# H6 register map
Vendor: Allwinner; Series: H6; File version: 0.1
CPU: CA53 0, little endian, MPU, no FPU, 0 interrupt priority bits
Registers are 32-bit, read-write, reset 0x0 unless marked. A register's access mark holds for its fields unless they carry their own. Offsets are from the block's base; [hi:lo] are bit positions; {n}, {i} and the like mark numbered series; 'fields as' and 'values as' point back to an identical list.

## PIO
Base 0x0300B000
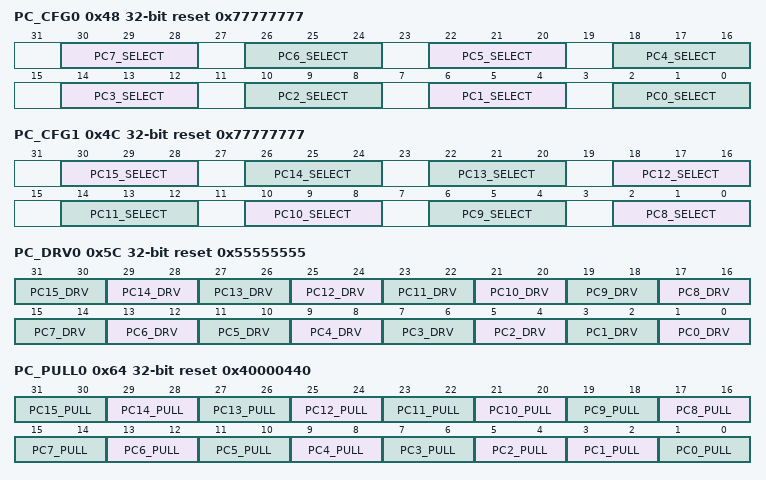
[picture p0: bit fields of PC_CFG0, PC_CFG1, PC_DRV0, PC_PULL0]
0x48 PC_CFG0 reset 0x77777777
  [30:28] PC7_SELECT — 000:Input 001:Output 010:NAND_DQ1 011:SDC2_D1 100:SPI0_WP 101:Reserved 110:Reserved 111:IO Disable
  [26:24] PC6_SELECT — 000:Input 001:Output 010:NAND_DQ0 011:SDC2_D0 100:SPI0_HOLD 101:Reserved 110:Reserved 111:IO Disable
  [22:20] PC5_SELECT — 000:Input 001:Output 010:NAND_RB0 011:SDC2_CMD 100:SPI0_CS 101:Reserved 110:Reserved 111:IO Disable
  [18:16] PC4_SELECT — 000:Input 001:Output 010:NAND_RE 011:SDC2_CLK 100:Reserved 101:Reserved 110:Reserved 111:IO Disable
  [14:12] PC3_SELECT — 000:Input 001:Output 010:NAND_CE0 011:Reserved 100:SPI0_MISO 101:Reserved 110:Reserved 111:IO Disable
  [10:8] PC2_SELECT — 000:Input 001:Output 010:NAND_CLE 011:Reserved 100:SPI0_MOSI 101:Reserved 110:Reserved 111:IO Disable
  [6:4] PC1_SELECT — 000:Input 001:Output 010:NAND_ALE 011:SDC2_DS 100:Reserved 101:Reserved 110:Reserved 111:IO Disable
  [2:0] PC0_SELECT — 000:Input 001:Output 010:NAND_WE 011:Reserved 100:SPI0_CLK 101:Reserved 110:Reserved 111:IO Disable
0x4C PC_CFG1 reset 0x77777777
  [30:28] PC15_SELECT — 000:Input 001:Output 010:NAND_CE1 011:Reserved 100:Reserved 101:Reserved 110:Reserved 111:IO Disable
  [26:24] PC14_SELECT — 000:Input 001:Output 010:NAND_DQS 011:SDC2_RST 100:Reserved 101:Reserved 110:Reserved 111:IO Disable
  [4n-30:4n-32] PC{n}_SELECT (n=8..13) — 000:Input 001:Output 010:NAND_DQ{n-6} 011:SDC2_D{n-6} 100:Reserved 101:Reserved 110:Reserved 111:IO Disable
0x50 PC_CFG2 reset 0x7
  [2:0] PC16_SELECT — 000:Input 001:Output 010:NAND_RB1 011:Reserved 100:Reserved 101:Reserved 110:Reserved 111:IO Disable
0x54 PC_CFG3 reset not defined
0x58 PC_DAT
  [16:0] PC_DAT — If the port is configured as input, the corresponding bit is the pin state. If the port is configured as output, the pin state is the same as the corresponding bit. The read bit value is the value setup by software. If the port is configured as functional pin, the undefined value will be read.
0x5C PC_DRV0 reset 0x55555555
  [all] fields
    {v}=Level_{v} (v=0..3)
  [2n+1:2n] PC{n}_DRV (n=0..15) — PC{n} Multi-Driving Select 00: Level 0 01: Level 1 10: Level 2 11: Level 3
0x60 PC_DRV1 reset 0x1
  [1:0] PC16_DRV — PC16 Multi-Driving Select 00: Level 0 01: Level 1 10: Level 2 11: Level 3
    {v}=Level_{v} (v=0..3)
0x64 PC_PULL0 reset 0x40000440
  [all] fields
    0=Pull_minus_up_slash_down_disable (Pull-up/down disable); 1=Pull_minus_up (Pull-up); 2=Pull_minus_down (Pull-down)
  [2n+1:2n] PC{n}_PULL (n=2..15) — PC{n} Pull-up/down Select 00: Pull-up/down disable 01: Pull-up 10: Pull-down 11: Reserved
  [3:2] PC1_PULL — PC Pull-up/down Select 00: Pull-up/down disable 01: Pull-up 10: Pull-down 11: Reserved
  [1:0] PC0_PULL — PC0 Pull-up/down Select 00: Pull-up/down disable 01: Pull-up 10: Pull-down 11: Reserved
0x68 PC_PULL1 reset 0x1
  [1:0] PC16_PULL — PC16 Pull-up/down Select 00: Pull-up/down disable 01: Pull-up 10: Pull-down 11: Reserved
    values as the fields of PC_PULL0
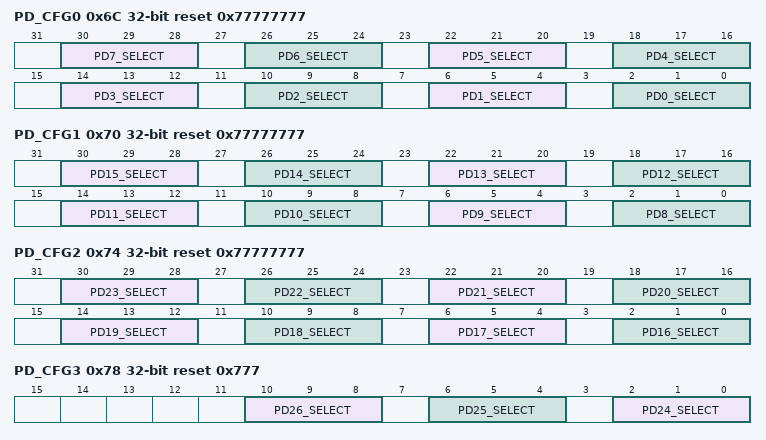
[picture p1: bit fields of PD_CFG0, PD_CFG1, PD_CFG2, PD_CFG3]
0x6C PD_CFG0 reset 0x77777777
  [30:28] PD7_SELECT — 000:Input 001:Output 010:LCD0_D11 011:TS0_D3 100:CSI_D3 101:RGMII_TXD3/RMII_NULL 110:Reserved 111:IO Disable
  [26:24] PD6_SELECT — 000:Input 001:Output 010:LCD0_D10 011:TS0_D2 100:CSI_D2 101:RGMII_NULL/RMII_RXER 110:Reserved 111:IO Disable
  [22:20] PD5_SELECT — 000:Input 001:Output 010:LCD0_D7 011:TS0_D1 100:CSI_D1 101:RGMII_RXCTL/RMII_CRS_DV 110:Reserved 111:IO Disable
  [18:16] PD4_SELECT — 000:Input 001:Output 010:LCD0_D6 011:TS0_D0 100:CSI_D0 101:RGMII_RXCK/RMII_NULL 110:Reserved 111:IO Disable
  [14:12] PD3_SELECT — 000:Input 001:Output 010:LCD0_D5 011:TS0_DVLD 100:CSI_VSYNC 101:RGMII_RXD0/RMII_RXD0 110:Reserved 111:IO Disable
  [10:8] PD2_SELECT — 000:Input 001:Output 010:LCD0_D4 011:TS0_SYNC 100:CSI_HSYNC 101:RGMII_RXD1/RMII_RXD1 110:Reserved 111:IO Disable
  [6:4] PD1_SELECT — 000:Input 001:Output 010:LCD0_D3 011:TS0_ERR 100:CSI_MCLK 101:RGMII_RXD2/RMII_NULL 110:Reserved 111:IO Disable
  [2:0] PD0_SELECT — 000:Input 001:Output 010:LCD0_D2 011:TS0_CLK 100:CSI_PCLK 101:RGMII_RXD3/RMII_NULL 110:Reserved 111:IO Disable
0x70 PD_CFG1 reset 0x77777777
  [30:28] PD15_SELECT — 000:Input 001:Output 010:LCD0_D21 011:TS1_DVLD 100:DMIC_DATA0 101:CSI_D9 110:Reserved 111:IO Disable
  [26:24] PD14_SELECT — 000:Input 001:Output 010:LCD0_D20 011:TS1_SYNC 100:DMIC_CLK 101:CSI_D8 110:Reserved 111:IO Disable
  [22:20] PD13_SELECT — 000:Input 001:Output 010:LCD0_D19 011:TS1_ERR 100:CSI_SDA 101:RGMII_CLKIN/RMII_NULL 110:Reserved 111:IO Disable
  [18:16] PD12_SELECT — 000:Input 001:Output 010:LCD0_D18 011:TS1_CLK 100:CSI_SCK 101:RGMII_TXCTL/RMII_TXEN 110:Reserved 111:IO Disable
  [14:12] PD11_SELECT — 000:Input 001:Output 010:LCD0_D15 011:TS0_D7 100:CSI_D7 101:RGMII_TXCK/RMII_TXCK 110:Reserved 111:IO Disable
  [10:8] PD10_SELECT — 000:Input 001:Output 010:LCD0_D14 011:TS0_D6 100:CSI_D6 101:RGMII_TXD0/RMII_TXD0 110:Reserved 111:IO Disable
  [6:4] PD9_SELECT — 000:Input 001:Output 010:LCD0_D13 011:TS0_D5 100:CSI_D5 101:RGMII_TXD1/RMII_TXD1 110:Reserved 111:IO Disable
  [2:0] PD8_SELECT — 000:Input 001:Output 010:LCD0_D12 011:TS0_D4 100:CSI_D4 101:RGMII_TXD2/RMII_NULL 110:Reserved 111:IO Disable
0x74 PD_CFG2 reset 0x77777777
  [30:28] PD23_SELECT — 000:Input 001:Output 010:TWI2_SCK 011:TS3_ERR 100:UART3_TX 101:JTAG_MS 110:Reserved 111:IO Disable
  [26:24] PD22_SELECT — 000:Input 001:Output 010:PWM0 011:TS3_CLK 100:UART2_CTS 101:Reserved 110:Reserved 111:IO Disable
  [22:20] PD21_SELECT — 000:Input 001:Output 010:LCD0_VSYNC 011:TS2_D0 100:UART2_RTS 101:Reserved 110:Reserved 111:IO Disable
  [18:16] PD20_SELECT — 000:Input 001:Output 010:LCD0_HSYNC 011:TS2_DVLD 100:UART2_RX 101:MDIO 110:Reserved 111:IO Disable
  [14:12] PD19_SELECT — 000:Input 001:Output 010:LCD0_DE 011:TS2_SYNC 100:UART2_TX 101:MDC 110:Reserved 111:IO Disable
  [10:8] PD18_SELECT — 000:Input 001:Output 010:LCD0_CLK 011:TS2_ERR 100:DMIC_DATA3 101:Reserved 110:Reserved 111:IO Disable
  [6:4] PD17_SELECT — 000:Input 001:Output 010:LCD0_D23 011:TS2_CLK 100:DMIC_DATA2 101:Reserved 110:Reserved 111:IO Disable
  [2:0] PD16_SELECT — 000:Input 001:Output 010:LCD0_D22 011:TS1_D0 100:DMIC_DATA1 101:Reserved 110:Reserved 111:IO Disable
0x78 PD_CFG3 reset 0x777
  [10:8] PD26_SELECT — 000:Input 001:Output 010:TWI0_SDA 011:TS3_D0 100:UART3_CTS 101:JTAG_DI 110:Reserved 111:IO Disable
  [6:4] PD25_SELECT — 000:Input 001:Output 010:TWI0_SCK 011:TS3_DVLD 100:UART3_RTS 101:JTAG_DO 110:Reserved 111:IO Disable
  [2:0] PD24_SELECT — 000:Input 001:Output 010:TWI2_SDA 011:TS3_SYNC 100:UART3_RX 101:JTAG_CK 110:Reserved 111:IO Disable
0x7C PD_DAT
  [26:0] PD_DAT — If the port is configured as input, the corresponding bit is the pin state. If the port is configured as output, the pin state is the same as the corresponding bit. The read bit value is the value setup by software. If the port is configured as functional pin, the undefined value will be read.
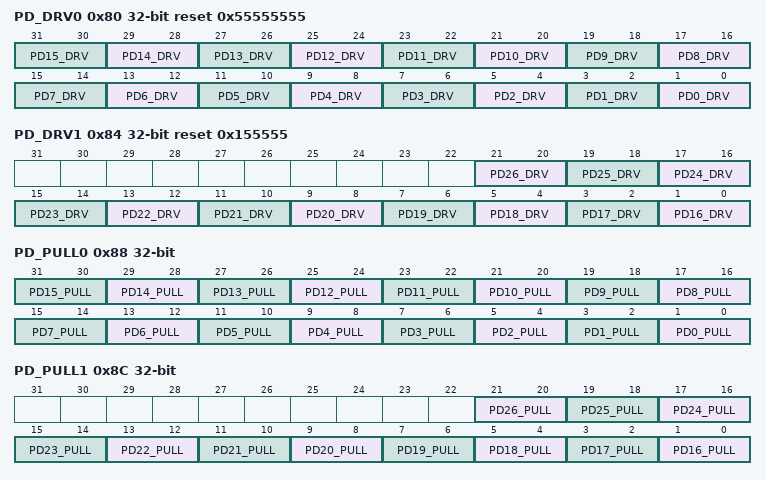
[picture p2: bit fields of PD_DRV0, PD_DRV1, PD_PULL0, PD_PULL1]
0x80 PD_DRV0 reset 0x55555555
  [all] fields
    {v}=Level_{v} (v=0..3)
  [2n+1:2n] PD{n}_DRV (n=0..15) — PD{n} Multi-Driving Select 00: Level 0 01: Level 1 10: Level 2 11: Level 3
0x84 PD_DRV1 reset 0x155555
  [all] fields
    {v}=Level_{v} (v=0..3)
  [2n-31:2n-32] PD{n}_DRV (n=16..26) — PD{n} Multi-Driving Select 00: Level 0 01: Level 1 10: Level 2 11: Level 3
0x88 PD_PULL0
  [all] fields
    values as the fields of PC_PULL0
  [2n+1:2n] PD{n}_PULL (n=0..15) — PD{n} Pull-up/down Select 00: Pull-up/down disable 01: Pull-up 10: Pull-down 11: Reserved
0x8C PD_PULL1
  [all] fields
    values as the fields of PC_PULL0
  [2n-31:2n-32] PD{n}_PULL (n=16..26) — PD{n} Pull-up/down Select 00: Pull-up/down disable 01: Pull-up 10: Pull-down 11: Reserved
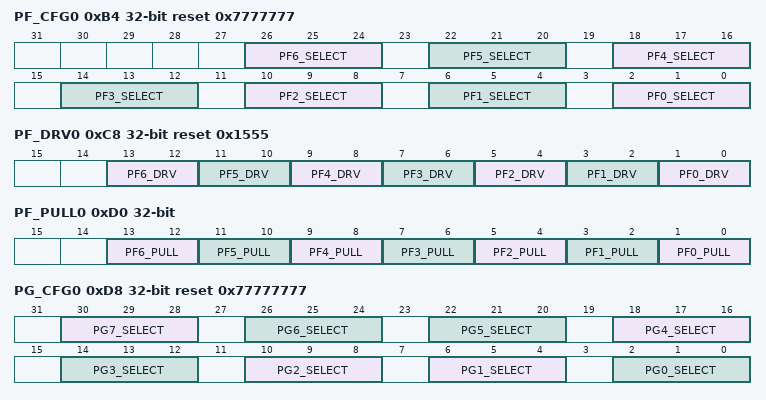
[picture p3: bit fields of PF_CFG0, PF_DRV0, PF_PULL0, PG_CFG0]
0xB4 PF_CFG0 reset 0x7777777
  [26:24] PF6_SELECT — 000:Input 001:Output 010:Reserved 011:Reserved 100:Reserved 101:Reserved 110:PF_EINT6 111:IO Disable
  [22:20] PF5_SELECT — 000:Input 001:Output 010:SDC0_D2 011:JTAG_CK1 100:Reserved 101:Reserved 110:PF_EINT5 111:IO Disable
  [18:16] PF4_SELECT — 000:Input 001:Output 010:SDC0_D3 011:UART0_RX 100:Reserved 101:Reserved 110:PF_EINT4 111:IO Disable
  [14:12] PF3_SELECT — 000:Input 001:Output 010:SDC0_CMD 011:JTAG_DO1 100:Reserved 101:Reserved 110:PF_EINT3 111:IO Disable
  [10:8] PF2_SELECT — 000:Input 001:Output 010:SDC0_CLK 011:UART0_TX 100:Reserved 101:Reserved 110:PF_EINT2 111:IO Disable
  [6:4] PF1_SELECT — 000:Input 001:Output 010:SDC0_D0 011:JTAG_DI1 100:Reserved 101:Reserved 110:PF_EINT1 111:IO Disable
  [2:0] PF0_SELECT — 000:Input 001:Output 010:SDC0_D1 011:JTAG_MS1 100:Reserved 101:Reserved 110:PF_EINT0 111:IO Disable
{0xB4+4i} PF_CFG{i} reset not defined (i=1..3)
0xC4 PF_DAT
  [6:0] PF_DAT — If the port is configured as input, the corresponding bit is the pin state. If the port is configured as output, the pin state is the same as the corresponding bit. The read bit value is the value setup by software. If the port is configured as functional pin, the undefined value will be read.
0xC8 PF_DRV0 reset 0x1555
  [all] fields
    {v}=Level_{v} (v=0..3)
  [2n+1:2n] PF{n}_DRV (n=0..6) — PF{n} Multi-Driving Select 00: Level 0 01: Level 1 10: Level 2 11: Level 3
0xCC PF_DRV1 reset not defined
0xD0 PF_PULL0
  [all] fields
    values as the fields of PC_PULL0
  [2n+1:2n] PF{n}_PULL (n=0..6) — PF{n} Pull-up/down Select 00: Pull-up/down disable 01: Pull-up 10: Pull-down 11: Reserved
0xD4 PF_PULL1 reset not defined
0xD8 PG_CFG0 reset 0x77777777
  [30:28] PG7_SELECT — 000:Input 001:Output 010:UART1_RX 011:Reserved 100:Reserved 101:Reserved 110:PG_EINT7 111:IO Disable
  [26:24] PG6_SELECT — 000:Input 001:Output 010:UART1_TX 011:Reserved 100:Reserved 101:Reserved 110:PG_EINT6 111:IO Disable
  [4n+2:4n] PG{n}_SELECT (n=2..5) — 000:Input 001:Output 010:SDC1_D{n-2} 011:Reserved 100:Reserved 101:Reserved 110:PG_EINT{n} 111:IO Disable
  [6:4] PG1_SELECT — 000:Input 001:Output 010:SDC1_CMD 011:Reserved 100:Reserved 101:Reserved 110:PG_EINT1 111:IO Disable
  [2:0] PG0_SELECT — 000:Input 001:Output 010:SDC1_CLK 011:Reserved 100:Reserved 101:Reserved 110:PG_EINT0 111:IO Disable
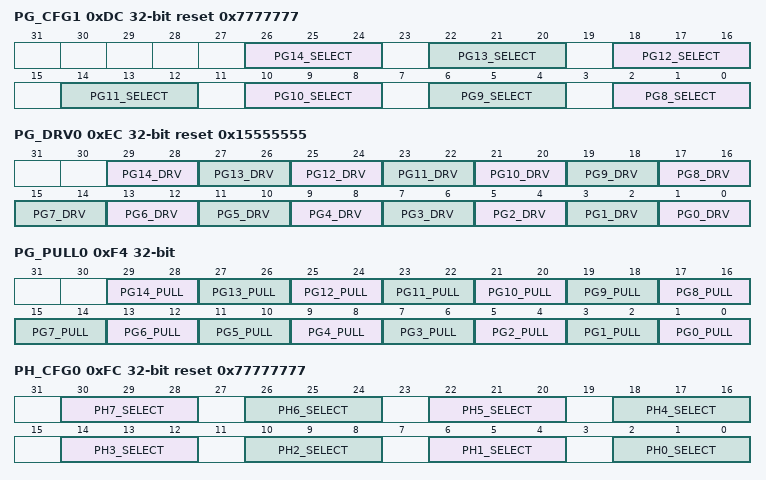
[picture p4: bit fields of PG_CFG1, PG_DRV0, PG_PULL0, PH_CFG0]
0xDC PG_CFG1 reset 0x7777777
  [26:24] PG14_SELECT — 000:Input 001:Output 010:PCM2_MCLK 011:H_PCM2_MCLK 100:SIM0_DET 101:Reserved 110:PG_EINT14 111:IO Disable
  [22:20] PG13_SELECT — 000:Input 001:Output 010:PCM2_DIN 011:H_PCM2_DIN 100:SIM0_RST 101:Reserved 110:PG_EINT13 111:IO Disable
  [18:16] PG12_SELECT — 000:Input 001:Output 010:PCM2_DOUT 011:H_PCM2_DOUT 100:SIM0_DATA 101:Reserved 110:PG_EINT12 111:IO Disable
  [14:12] PG11_SELECT — 000:Input 001:Output 010:PCM2_CLK 011:H_PCM2_CLK 100:SIM0_CLK 101:Reserved 110:PG_EINT11 111:IO Disable
  [10:8] PG10_SELECT — 000:Input 001:Output 010:PCM2_SYNC 011:H_PCM2_SYNC 100:SIM0_PWREN 101:Reserved 110:PG_EINT10 111:IO Disable
  [6:4] PG9_SELECT — 000:Input 001:Output 010:UART1_CTS 011:Reserved 100:SIM0_VPPPP 101:Reserved 110:PG_EINT9 111:IO Disable
  [2:0] PG8_SELECT — 000:Input 001:Output 010:UART1_RTS 011:Reserved 100:SIM0_VPPEN 101:Reserved 110:PG_EINT8 111:IO Disable
0xE0 PG_CFG2 reset not defined
0xE4 PG_CFG3 reset not defined
0xE8 PG_DAT
  [14:0] PG_DAT — If the port is configured as input, the corresponding bit is the pin state. If the port is configured as output, the pin state is the same as the corresponding bit. The read bit value is the value setup by software. If the port is configured as functional pin, the undefined value will be read.
0xEC PG_DRV0 reset 0x15555555
  [all] fields
    {v}=Level_{v} (v=0..3)
  [2n+1:2n] PG{n}_DRV (n=0..14) — PG{n} Multi-Driving Select 00: Level 0 01: Level 1 10: Level 2 11: Level 3
0xF0 PG_DRV1 reset not defined
0xF4 PG_PULL0
  [all] fields
    values as the fields of PC_PULL0
  [2n+1:2n] PG{n}_PULL (n=0..14) — PG{n} Pull-up/down Select 00: Pull-up/down disable 01: Pull-up 10: Pull-down 11: Reserved
0xF8 PG_PULL1 reset not defined
0xFC PH_CFG0 reset 0x77777777
  [30:28] PH7_SELECT — 000:Input 001:Output 010:Reserved 011:OWA_OUT 100:Reserved 101:Reserved 110:PH_EINT7 111:IO Disable
  [26:24] PH6_SELECT — 000:Input 001:Output 010:SPI1_MISO 011:OWA_IN 100:TWI1_SDA 101:SIM1_DET 110:PH_EINT6 111:IO Disable
  [22:20] PH5_SELECT — 000:Input 001:Output 010:SPI1_MOSI 011:OWA_MCLK 100:TWI1_SCK 101:SIM1_RST 110:PH_EINT5 111:IO Disable
  [18:16] PH4_SELECT — 000:Input 001:Output 010:SPI1_CLK 011:PCM0_MCLK 100:H_PCM0_MCLK 101:SIM1_DATA 110:PH_EINT4 111:IO Disable
  [14:12] PH3_SELECT — 000:Input 001:Output 010:SPI1_CS 011:PCM0_DIN 100:H_PCM0_DIN 101:SIM1_CLK 110:PH_EINT3 111:IO Disable
  [10:8] PH2_SELECT — 000:Input 001:Output 010:CIR_TX 011:PCM0_DOUT 100:H_PCM0_DOUT 101:SIM1_PWREN 110:PH_EINT2 111:IO Disable
  [6:4] PH1_SELECT — 000:Input 001:Output 010:UART0_RX 011:PCM0_CLK 100:H_PCM0_CLK 101:SIM1_VPPPP 110:PH_EINT1 111:IO Disable
  [2:0] PH0_SELECT — 000:Input 001:Output 010:UART0_TX 011:PCM0_SYNC 100:H_PCM0_SYNC 101:SIM1_VPPEN 110:PH_EINT0 111:IO Disable
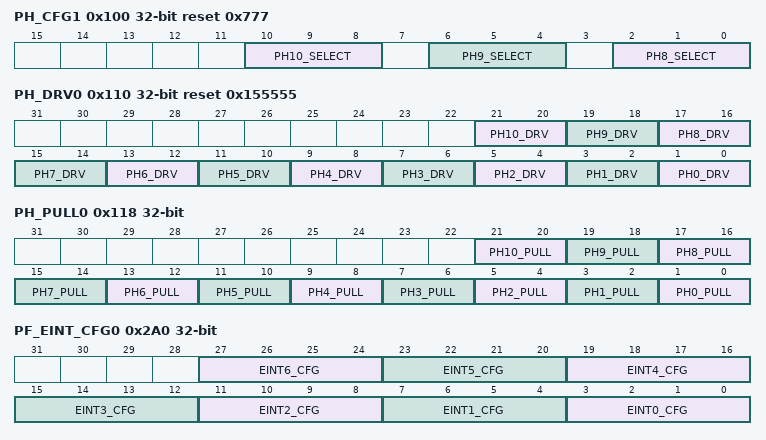
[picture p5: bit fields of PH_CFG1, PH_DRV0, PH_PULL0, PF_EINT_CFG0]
0x100 PH_CFG1 reset 0x777
  [10:8] PH10_SELECT — 000:Input 001:Output 010:HCEC 011:Reserved 100:Reserved 101:Reserved 110:PH_EINT10 111:IO Disable
  [6:4] PH9_SELECT — 000:Input 001:Output 010:HSDA 011:Reserved 100:Reserved 101:Reserved 110:PH_EINT9 111:IO Disable
  [2:0] PH8_SELECT — 000:Input 001:Output 010:HSCL 011:Reserved 100:Reserved 101:Reserved 110:PH_EINT8 111:IO Disable
0x104 PH_CFG2 reset not defined
0x108 PH_CFG3 reset not defined
0x10C PH_DAT
  [10:0] PH_DAT — If the port is configured as input, the corresponding bit is the pin state. If the port is configured as output, the pin state is the same as the corresponding bit. The read bit value is the value setup by software. If the port is configured as functional pin, the undefined value will be read.
0x110 PH_DRV0 reset 0x155555
  [all] fields
    {v}=Level_{v} (v=0..3)
  [2n+1:2n] PH{n}_DRV (n=0..10) — PH{n} Multi-Driving Select 00: Level 0 01: Level 1 10: Level 2 11: Level 3
0x114 PH_DRV1 reset not defined
0x118 PH_PULL0
  [all] fields
    values as the fields of PC_PULL0
  [2n+1:2n] PH{n}_PULL (n=0..10) — PH{n} Pull-up/down Select 00: Pull-up/down disable 01: Pull-up 10: Pull-down 11: Reserved
0x11C PH_PULL1 reset not defined
0x2A0 PF_EINT_CFG0
  [all] fields
    0=Positive_Edge; 1=Negative_Edge; 2=High_Level; 3=Low_Level; 4=Double Edge (Positive/ Negative) Others: Reserved
  [4n+3:4n] EINT{n}_CFG (n=0..6) — External INT{n} Mode 0000: Positive Edge 0001: Negative Edge 0010: High Level 0011: Low Level 0100: Double Edge (Positive/ Negative) Others: Reserved
{0x2A0+4i} PF_EINT_CFG{i} reset not defined (i=1..3)
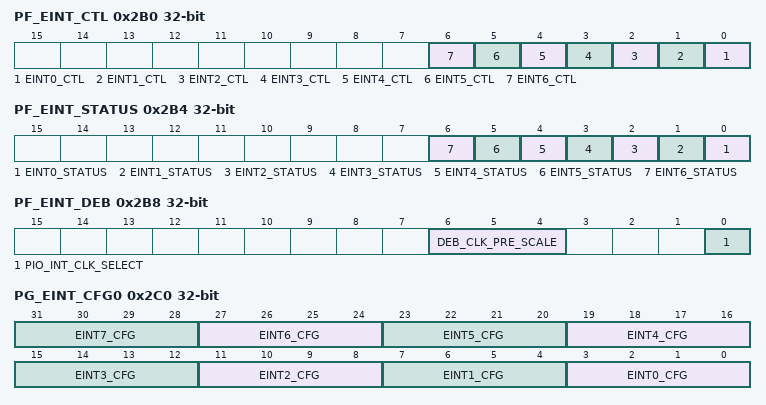
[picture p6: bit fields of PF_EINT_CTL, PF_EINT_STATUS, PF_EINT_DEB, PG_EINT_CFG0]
0x2B0 PF_EINT_CTL
  [all] fields
    0=Disable; 1=Enable
  [n] EINT{n}_CTL (n=0..6) — External INT{n} Enable 0: Disable 1: Enable
0x2B4 PF_EINT_STATUS
  [all] fields
    0=No IRQ pending; 1=IRQ pending Write `1` to clear
  [n] EINT{n}_STATUS (n=0..6) — External INT{n} Pending Bit 0: No IRQ pending 1: IRQ pending Write `1` to clear
0x2B8 PF_EINT_DEB
  [6:4] DEB_CLK_PRE_SCALE — Debounce Clock Pre-scale n The selected clock source is prescaled by 2^n.
  [0] PIO_INT_CLK_SELECT — PIO Interrupt Clock Select 0: LOSC 32KHz 1: HOSC 24MHz
    0=LOSC (LOSC 32KHz); 1=HOSC (HOSC 24MHz)
0x2C0 PG_EINT_CFG0
  [all] fields
    values as the fields of PF_EINT_CFG0
  [4n+3:4n] EINT{n}_CFG (n=0..7) — External INT{n} Mode 0000: Positive Edge 0001: Negative Edge 0010: High Level 0011: Low Level 0100: Double Edge (Positive/ Negative) Others: Reserved
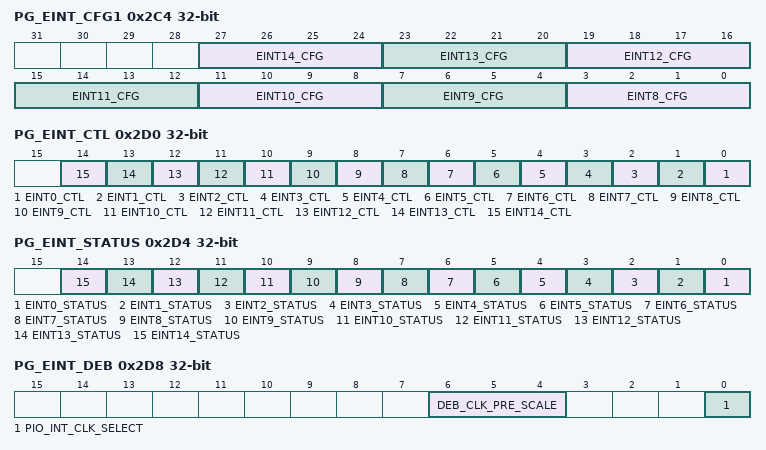
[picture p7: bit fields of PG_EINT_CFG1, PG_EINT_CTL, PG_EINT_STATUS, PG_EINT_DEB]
0x2C4 PG_EINT_CFG1
  [all] fields
    values as the fields of PF_EINT_CFG0
  [4n-29:4n-32] EINT{n}_CFG (n=8..14) — External INT{n} Mode 0000: Positive Edge 0001: Negative Edge 0010: High Level 0011: Low Level 0100: Double Edge (Positive/ Negative) Others: Reserved
0x2C8 PG_EINT_CFG2 reset not defined
0x2CC PG_EINT_CFG3 reset not defined
0x2D0 PG_EINT_CTL
  [all] fields
    0=Disable; 1=Enable
  [n] EINT{n}_CTL (n=0..14) — External INT{n} Enable 0: Disable 1: Enable
0x2D4 PG_EINT_STATUS
  [all] fields
    0=No IRQ pending; 1=IRQ pending Write `1` to clear
  [n] EINT{n}_STATUS (n=0..14) — External INT{n} Pending Bit 0: No IRQ pending 1: IRQ pending Write `1` to clear
0x2D8 PG_EINT_DEB
  fields as PF_EINT_DEB
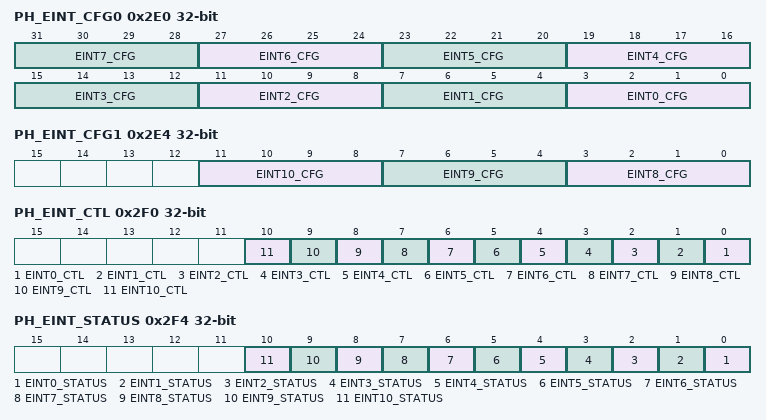
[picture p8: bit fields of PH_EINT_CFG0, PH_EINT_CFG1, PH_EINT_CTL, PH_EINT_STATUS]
0x2E0 PH_EINT_CFG0
  fields as PG_EINT_CFG0
0x2E4 PH_EINT_CFG1
  [all] fields
    values as the fields of PF_EINT_CFG0
  [11:8] EINT10_CFG — External INT10 Mode 0000: Positive Edge 0001: Negative Edge 0010: High Level 0011: Low Level 0100: Double Edge (Positive/ Negative) Others: Reserved
  [7:4] EINT9_CFG — External INT9 Mode 0000: Positive Edge 0001: Negative Edge 0010: High Level 0011: Low Level 0100: Double Edge (Positive/ Negative) Others: Reserved
  [3:0] EINT8_CFG — External INT8 Mode 0000: Positive Edge 0001: Negative Edge 0010: High Level 0011: Low Level 0100: Double Edge (Positive/ Negative) Others: Reserved
0x2E8 PH_EINT_CFG2 reset not defined
0x2EC PH_EINT_CFG3 reset not defined
0x2F0 PH_EINT_CTL
  [all] fields
    0=Disable; 1=Enable
  [n] EINT{n}_CTL (n=0..10) — External INT{n} Enable 0: Disable 1: Enable
0x2F4 PH_EINT_STATUS
  [all] fields
    0=No IRQ pending; 1=IRQ pending Write `1` to clear
  [n] EINT{n}_STATUS (n=0..10) — External INT{n} Pending Bit 0: No IRQ pending 1: IRQ pending Write `1` to clear
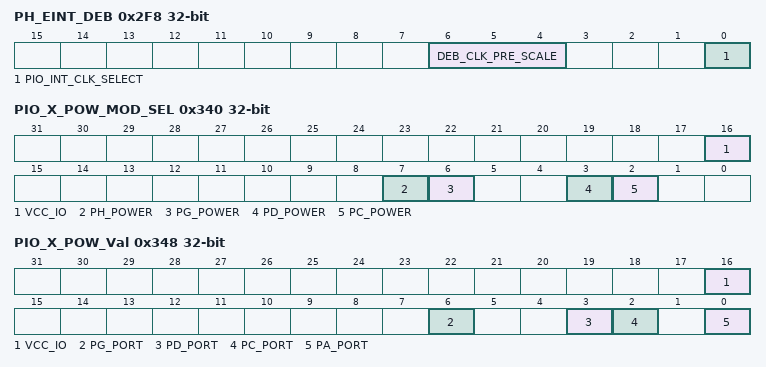
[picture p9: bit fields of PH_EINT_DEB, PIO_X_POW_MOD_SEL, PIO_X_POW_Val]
0x2F8 PH_EINT_DEB
  fields as PF_EINT_DEB
0x340 PIO_X_POW_MOD_SEL (reset mask 0x1004C)
  [16] VCC_IO — POWER MODE Select 0: 3.3V 1: 1.8V
    0=_3_point_3V (3.3V); 1=_1_point_8V (1.8V)
  [7] PH_POWER — MODE Select invalid
  [6] PG_POWER — MODE Select 0: 3.3V 1: 1.8V If PG_Port Power Source selects VCC-IO,this bit is invalid
    0=_3_point_3V (3.3V); 1=_1_point_8V (1.8V If PG_Port Power Source selects VCC-IO,this bit is invalid)
  [3] PD_POWER — MODE Select 0: 3.3V 1: 1.8V If PD_Port Power Source selects VCC-IO,this bit is invalid
    0=_3_point_3V (3.3V); 1=_1_point_8V (1.8V If PD_Port Power Source selects VCC-IO,this bit is invalid)
  [2] PC_POWER — MODE Select 0: 3.3V 1: 1.8V If PC_Port Power Source selects VCC-IO,this bit is invalid
    0=_3_point_3V (3.3V); 1=_1_point_8V (1.8V If PC_Port Power Source selects VCC-IO,this bit is invalid)
0x348 PIO_X_POW_Val reset not defined
  [16] VCC_IO ro — Power Value
  [6] PG_PORT ro — Power Value If PG_Port Power Source selects VCC-IO,this bit is invalid
  [3] PD_PORT ro — Power Value If PD_Port Power Source selects VCC-IO,this bit is invalid
  [2] PC_PORT ro — Power Value If PC_Port Power Source selects VCC-IO,this bit is invalid
  [0] PA_PORT ro — Power Value invalid
